# STM32L062 register map
File version: 1.2
CPU: CM0+ r0p0, little endian, MPU, no FPU, 4 interrupt priority bits
Registers are 32-bit, read-write, reset 0x0 unless marked. A register's access mark holds for its fields unless they carry their own. Offsets are from the block's base; [hi:lo] are bit positions; {n}, {i} and the like mark numbered series.

## CRS — Clock recovery system
Base 0x40006C00
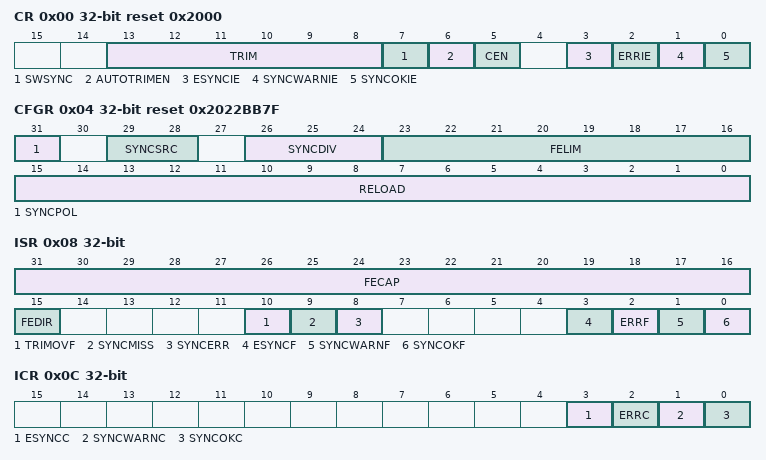
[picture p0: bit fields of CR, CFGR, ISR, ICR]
0x00 CR reset 0x2000 — control register
  [13:8] TRIM — HSI48 oscillator smooth trimming
  [7] SWSYNC — Generate software SYNC event
  [6] AUTOTRIMEN — Automatic trimming enable
  [5] CEN — Frequency error counter enable
  [3] ESYNCIE — Expected SYNC interrupt enable
  [2] ERRIE — Synchronization or trimming error interrupt enable
  [1] SYNCWARNIE — SYNC warning interrupt enable
  [0] SYNCOKIE — SYNC event OK interrupt enable
0x04 CFGR reset 0x2022BB7F — configuration register
  [31] SYNCPOL — SYNC polarity selection
  [29:28] SYNCSRC — SYNC signal source selection
  [26:24] SYNCDIV — SYNC divider
  [23:16] FELIM — Frequency error limit
  [15:0] RELOAD — Counter reload value
0x08 ISR ro — interrupt and status register
  [31:16] FECAP — Frequency error capture
  [15] FEDIR — Frequency error direction
  [10] TRIMOVF — Trimming overflow or underflow
  [9] SYNCMISS — SYNC missed
  [8] SYNCERR — SYNC error
  [3] ESYNCF — Expected SYNC flag
  [2] ERRF — Error flag
  [1] SYNCWARNF — SYNC warning flag
  [0] SYNCOKF — SYNC event OK flag
0x0C ICR — interrupt flag clear register
  [3] ESYNCC — Expected SYNC clear flag
  [2] ERRC — Error clear flag
  [1] SYNCWARNC — SYNC warning clear flag
  [0] SYNCOKC — SYNC event OK clear flag

## Firewall
Base 0x40011C00
0x00 FIREWALL_CSSA — Code segment start address
  [23:8] ADD — code segment start address
0x04 FIREWALL_CSL — Code segment length
  [21:8] LENG — code segment length
0x08 FIREWALL_NVDSSA — Non-volatile data segment start address
  [23:8] ADD
0x0C FIREWALL_NVDSL — Non-volatile data segment length
  [21:8] LENG
0x10 FIREWALL_VDSSA — Volatile data segment start address
  [15:6] ADD
0x14 FIREWALL_VDSL — Volatile data segment length
  [15:6] LENG — Non-volatile data segment length
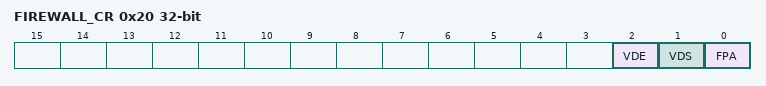
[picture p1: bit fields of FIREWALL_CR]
0x20 FIREWALL_CR — Configuration register
  [2] VDE — Volatile data execution
  [1] VDS — Volatile data shared
  [0] FPA — Firewall pre alarm

## SYSCFG_COMP — System configuration controller and Comparator
Base 0x40010000
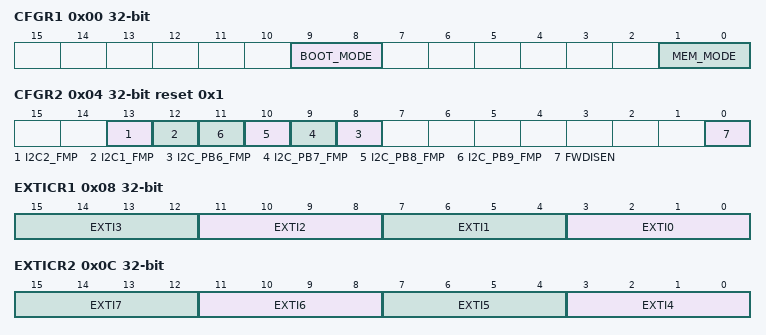
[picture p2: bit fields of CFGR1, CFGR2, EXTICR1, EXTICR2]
0x00 CFGR1 access per field — SYSCFG configuration register 1
  [9:8] BOOT_MODE ro — Boot mode selected by the boot pins status bits
  [1:0] MEM_MODE rw — Memory mapping selection bits
0x04 CFGR2 reset 0x1 — SYSCFG configuration register 2
  [13] I2C2_FMP — I2C2 Fm+ drive capability enable bit
  [12] I2C1_FMP — I2C1 Fm+ drive capability enable bit
  [n+2] I2C_PB{n}_FMP (n=6..9) — Fm+ drive capability on PB{n} enable bit
  [0] FWDISEN — Firewall disable bit
0x08 EXTICR1 — external interrupt configuration register 1
  [4n+3:4n] EXTI{n} (n=0..3) — EXTI x configuration (x = 0 to 3)
0x0C EXTICR2 — external interrupt configuration register 2
  [4n-13:4n-16] EXTI{n} (n=4..7) — EXTI x configuration (x = 4 to 7)
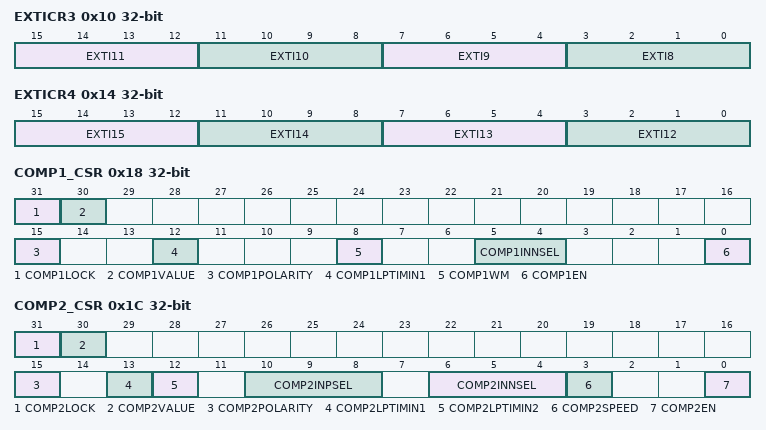
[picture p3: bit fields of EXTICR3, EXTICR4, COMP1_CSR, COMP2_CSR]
0x10 EXTICR3 — external interrupt configuration register 3
  [15:12] EXTI11 — EXTI x configuration (x = 8 to 11)
  [11:8] EXTI10
  [7:4] EXTI9 — EXTI x configuration (x = 8 to 11)
  [3:0] EXTI8 — EXTI x configuration (x = 8 to 11)
0x14 EXTICR4 — external interrupt configuration register 4
  [15:12] EXTI15 — EXTI x configuration (x = 12 to 15)
  [11:8] EXTI14
  [7:4] EXTI13
  [3:0] EXTI12
0x18 COMP1_CSR access per field — Comparator 1 control and status register
  [31] COMP1LOCK ro — COMP1_CSR register lock bit
  [30] COMP1VALUE ro — Comparator 1 output status bit
  [15] COMP1POLARITY rw — Comparator 1 polarity selection bit
  [12] COMP1LPTIMIN1 rw — Comparator 1 LPTIM input propagation bit
  [8] COMP1WM rw — Comparator 1 window mode selection bit
  [5:4] COMP1INNSEL rw — Comparator 1 Input Minus connection configuration bit
  [0] COMP1EN rw — Comparator 1 enable bit
0x1C COMP2_CSR access per field — Comparator 2 control and status register
  [31] COMP2LOCK ro — COMP2_CSR register lock bit
  [30] COMP2VALUE ro — Comparator 2 output status bit
  [15] COMP2POLARITY rw — Comparator 2 polarity selection bit
  [13] COMP2LPTIMIN1 rw — Comparator 2 LPTIM input 1 propagation bit
  [12] COMP2LPTIMIN2 rw — Comparator 2 LPTIM input 2 propagation bit
  [10:8] COMP2INPSEL rw — Comparator 2 Input Plus connection configuration bit
  [6:4] COMP2INNSEL rw — Comparator 2 Input Minus connection configuration bit
  [3] COMP2SPEED rw — Comparator 2 power mode selection bit
  [0] COMP2EN rw — Comparator 2 enable bit
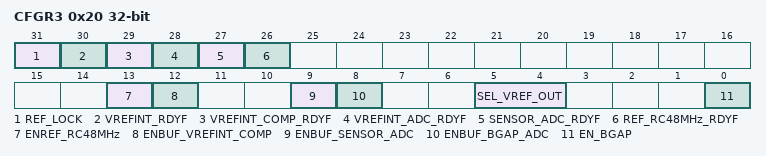
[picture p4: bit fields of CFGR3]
0x20 CFGR3 access per field — SYSCFG configuration register 3
  [31] REF_LOCK wo — REF_CTRL lock bit
  [30] VREFINT_RDYF ro — VREFINT ready flag
  [29] VREFINT_COMP_RDYF ro — VREFINT for comparator ready flag
  [28] VREFINT_ADC_RDYF ro — VREFINT for ADC ready flag
  [27] SENSOR_ADC_RDYF ro — Sensor for ADC ready flag
  [26] REF_RC48MHz_RDYF ro — VREFINT for 48 MHz RC oscillator ready flag
  [13] ENREF_RC48MHz rw — VREFINT reference for 48 MHz RC oscillator enable bit
  [12] ENBUF_VREFINT_COMP rw — VREFINT reference for comparator 2 enable bit
  [9] ENBUF_SENSOR_ADC rw — Sensor reference for ADC enable bit
  [8] ENBUF_BGAP_ADC rw — VREFINT reference for ADC enable bit
  [5:4] SEL_VREF_OUT rw — BGAP_ADC connection bit
  [0] EN_BGAP rw — Vref Enable bit
